AUTOSAR XML (schema 4-2-2)
package /EthernetModule
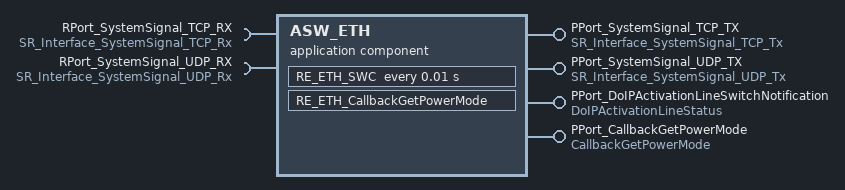
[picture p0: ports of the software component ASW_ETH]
  application sw component type ASW_ETH
    provide port PPort_SystemSignal_TCP_TX: provided-interface=SR_Interface_SystemSignal_TCP_Tx
    require port RPort_SystemSignal_TCP_RX: required-interface=SR_Interface_SystemSignal_TCP_Rx
    provide port PPort_SystemSignal_UDP_TX: provided-interface=SR_Interface_SystemSignal_UDP_Tx
    require port RPort_SystemSignal_UDP_RX: required-interface=SR_Interface_SystemSignal_UDP_Rx
    provide port PPort_DoIPActivationLineSwitchNotification: provided-interface=DoIPActivationLineStatus
    provide port PPort_CallbackGetPowerMode: provided-interface=CallbackGetPowerMode
    behavior IB_ETH_SWC: data-type-mapping=[DataTypeMappingSet, DTS_DoIP_ActivationLineType]
      timing event TE_ETH_SWC_10ms: start-on-event=RE_ETH_SWC, period=0.01
      operation invoked event OIE_CallbackGetPowerMode: start-on-event=RE_ETH_CallbackGetPowerMode, operation=PPort_CallbackGetPowerMode.GetPowerMode
      runnable RE_ETH_SWC
        data-read-access:
          access DRA_RPort_SystemSignal_TCP_RX_0: accessed-variable=RPort_SystemSignal_TCP_RX.RPort_SystemSignal_TCP_RX
          access DRA_RPort_SystemSignal_UDP_RX_0: accessed-variable=RPort_SystemSignal_UDP_RX.RPort_SystemSignal_UDP_RX
        data-send-points:
          access DSP_PPort_SystemSignal_TCP_TX_0: accessed-variable=PPort_SystemSignal_TCP_TX.PPort_SystemSignal_TCP_TX
          access DSP_RPort_SystemSignal_UDP_TX_0: accessed-variable=PPort_SystemSignal_UDP_TX.PPort_SystemSignal_UDP_TX
        mode switch point ModeSwitchPoint_0: mode-group=PPort_DoIPActivationLineSwitchNotification.currentDoIPActivationLineStatus
      runnable RE_ETH_CallbackGetPowerMode: symbol=RE_ETH_CallbackGetPowerMode_func
